# ESP32C3 register map
File version: 1.0
CPU: RISC-V RV32IMC single-core 1, little endian, no MPU, FPU, 3 interrupt priority bits
Registers are 32-bit, read-write, reset 0x0 unless marked. A register's access mark holds for its fields unless they carry their own. Offsets are from the block's base; [hi:lo] are bit positions; {n}, {i} and the like mark numbered series.

## SPI_MEM
Base 0x00000000
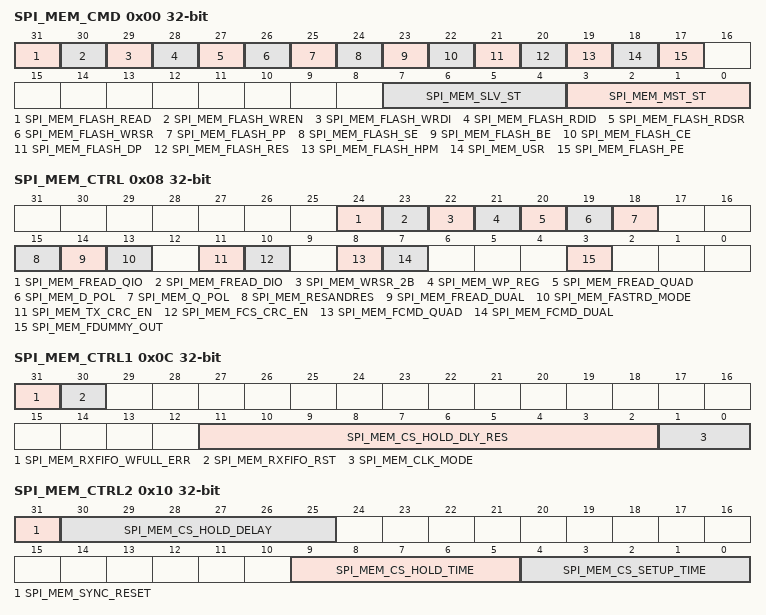
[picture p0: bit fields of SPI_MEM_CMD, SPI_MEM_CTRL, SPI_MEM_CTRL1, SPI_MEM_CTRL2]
0x00 SPI_MEM_CMD access per field
  [31] SPI_MEM_FLASH_READ rw, [30] SPI_MEM_FLASH_WREN rw, [29] SPI_MEM_FLASH_WRDI rw, [28] SPI_MEM_FLASH_RDID rw, [27] SPI_MEM_FLASH_RDSR rw, [26] SPI_MEM_FLASH_WRSR rw, [25] SPI_MEM_FLASH_PP rw, [24] SPI_MEM_FLASH_SE rw, [23] SPI_MEM_FLASH_BE rw, [22] SPI_MEM_FLASH_CE rw, [21] SPI_MEM_FLASH_DP rw, [20] SPI_MEM_FLASH_RES rw, [19] SPI_MEM_FLASH_HPM rw, [18] SPI_MEM_USR rw, [17] SPI_MEM_FLASH_PE rw, [7:4] SPI_MEM_SLV_ST ro, [3:0] SPI_MEM_MST_ST ro
0x04 SPI_MEM_ADDR
  [31:0] SPI_MEM_USR_ADDR_VALUE
0x08 SPI_MEM_CTRL
  [24] SPI_MEM_FREAD_QIO, [23] SPI_MEM_FREAD_DIO, [22] SPI_MEM_WRSR_2B, [21] SPI_MEM_WP_REG, [20] SPI_MEM_FREAD_QUAD, [19] SPI_MEM_D_POL, [18] SPI_MEM_Q_POL, [15] SPI_MEM_RESANDRES, [14] SPI_MEM_FREAD_DUAL, [13] SPI_MEM_FASTRD_MODE, [11] SPI_MEM_TX_CRC_EN, [10] SPI_MEM_FCS_CRC_EN, [8] SPI_MEM_FCMD_QUAD, [7] SPI_MEM_FCMD_DUAL, [3] SPI_MEM_FDUMMY_OUT
0x0C SPI_MEM_CTRL1 access per field
  [31] SPI_MEM_RXFIFO_WFULL_ERR ro, [30] SPI_MEM_RXFIFO_RST wo, [11:2] SPI_MEM_CS_HOLD_DLY_RES rw, [1:0] SPI_MEM_CLK_MODE rw
0x10 SPI_MEM_CTRL2 access per field
  [31] SPI_MEM_SYNC_RESET wo, [30:25] SPI_MEM_CS_HOLD_DELAY rw, [9:5] SPI_MEM_CS_HOLD_TIME rw, [4:0] SPI_MEM_CS_SETUP_TIME rw
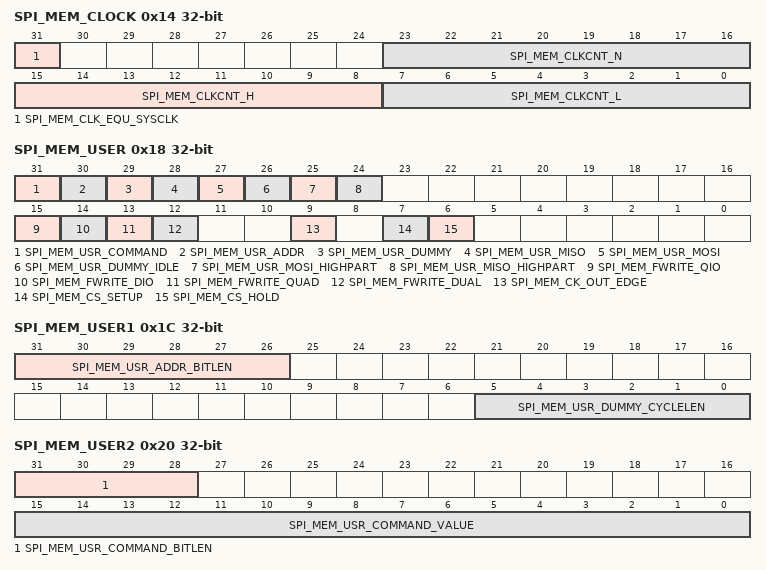
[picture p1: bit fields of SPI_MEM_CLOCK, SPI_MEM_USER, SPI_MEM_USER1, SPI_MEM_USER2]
0x14 SPI_MEM_CLOCK
  [31] SPI_MEM_CLK_EQU_SYSCLK, [23:16] SPI_MEM_CLKCNT_N, [15:8] SPI_MEM_CLKCNT_H, [7:0] SPI_MEM_CLKCNT_L
0x18 SPI_MEM_USER
  [31] SPI_MEM_USR_COMMAND, [30] SPI_MEM_USR_ADDR, [29] SPI_MEM_USR_DUMMY, [28] SPI_MEM_USR_MISO, [27] SPI_MEM_USR_MOSI, [26] SPI_MEM_USR_DUMMY_IDLE, [25] SPI_MEM_USR_MOSI_HIGHPART, [24] SPI_MEM_USR_MISO_HIGHPART, [15] SPI_MEM_FWRITE_QIO, [14] SPI_MEM_FWRITE_DIO, [13] SPI_MEM_FWRITE_QUAD, [12] SPI_MEM_FWRITE_DUAL, [9] SPI_MEM_CK_OUT_EDGE, [7] SPI_MEM_CS_SETUP, [6] SPI_MEM_CS_HOLD
0x1C SPI_MEM_USER1
  [31:26] SPI_MEM_USR_ADDR_BITLEN, [5:0] SPI_MEM_USR_DUMMY_CYCLELEN
0x20 SPI_MEM_USER2
  [31:28] SPI_MEM_USR_COMMAND_BITLEN, [15:0] SPI_MEM_USR_COMMAND_VALUE
0x24 SPI_MEM_MOSI_DLEN
  [9:0] SPI_MEM_USR_MOSI_DBITLEN
0x28 SPI_MEM_MISO_DLEN
  [9:0] SPI_MEM_USR_MISO_DBITLEN
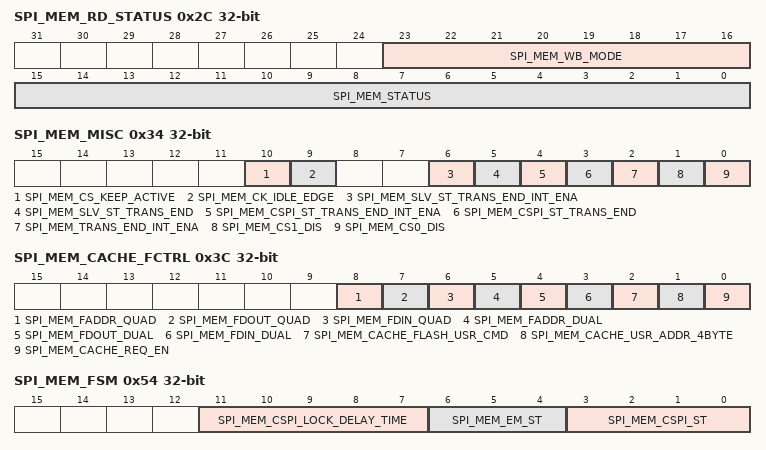
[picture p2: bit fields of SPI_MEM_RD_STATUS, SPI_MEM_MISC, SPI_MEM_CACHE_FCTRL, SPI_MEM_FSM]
0x2C SPI_MEM_RD_STATUS
  [23:16] SPI_MEM_WB_MODE, [15:0] SPI_MEM_STATUS
0x34 SPI_MEM_MISC
  [10] SPI_MEM_CS_KEEP_ACTIVE, [9] SPI_MEM_CK_IDLE_EDGE, [6] SPI_MEM_SLV_ST_TRANS_END_INT_ENA, [5] SPI_MEM_SLV_ST_TRANS_END, [4] SPI_MEM_CSPI_ST_TRANS_END_INT_ENA, [3] SPI_MEM_CSPI_ST_TRANS_END, [2] SPI_MEM_TRANS_END_INT_ENA, [1] SPI_MEM_CS1_DIS, [0] SPI_MEM_CS0_DIS
0x38 SPI_MEM_TX_CRC ro
  [31:0] SPI_MEM_TX_CRC_DATA
0x3C SPI_MEM_CACHE_FCTRL
  [8] SPI_MEM_FADDR_QUAD, [7] SPI_MEM_FDOUT_QUAD, [6] SPI_MEM_FDIN_QUAD, [5] SPI_MEM_FADDR_DUAL, [4] SPI_MEM_FDOUT_DUAL, [3] SPI_MEM_FDIN_DUAL, [2] SPI_MEM_CACHE_FLASH_USR_CMD, [1] SPI_MEM_CACHE_USR_ADDR_4BYTE, [0] SPI_MEM_CACHE_REQ_EN
0x54 SPI_MEM_FSM access per field
  [11:7] SPI_MEM_CSPI_LOCK_DELAY_TIME rw, [6:4] SPI_MEM_EM_ST ro, [3:0] SPI_MEM_CSPI_ST ro
{0x58+4i} SPI_MEM_W{i} (i=0..15)
  [31:0] SPI_MEM_BUF{i}
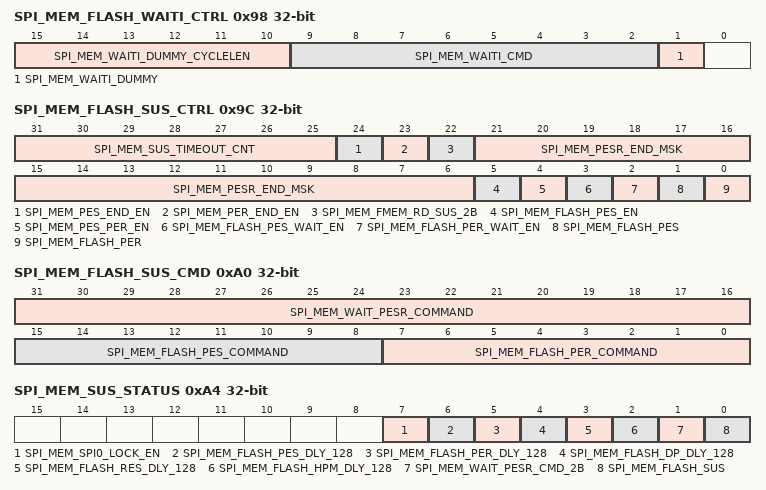
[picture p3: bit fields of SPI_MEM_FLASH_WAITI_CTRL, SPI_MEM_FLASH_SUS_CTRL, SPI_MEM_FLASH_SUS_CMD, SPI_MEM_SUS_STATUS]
0x98 SPI_MEM_FLASH_WAITI_CTRL
  [15:10] SPI_MEM_WAITI_DUMMY_CYCLELEN, [9:2] SPI_MEM_WAITI_CMD, [1] SPI_MEM_WAITI_DUMMY
0x9C SPI_MEM_FLASH_SUS_CTRL
  [31:25] SPI_MEM_SUS_TIMEOUT_CNT, [24] SPI_MEM_PES_END_EN, [23] SPI_MEM_PER_END_EN, [22] SPI_MEM_FMEM_RD_SUS_2B, [21:6] SPI_MEM_PESR_END_MSK, [5] SPI_MEM_FLASH_PES_EN, [4] SPI_MEM_PES_PER_EN, [3] SPI_MEM_FLASH_PES_WAIT_EN, [2] SPI_MEM_FLASH_PER_WAIT_EN, [1] SPI_MEM_FLASH_PES, [0] SPI_MEM_FLASH_PER
0xA0 SPI_MEM_FLASH_SUS_CMD
  [31:16] SPI_MEM_WAIT_PESR_COMMAND, [15:8] SPI_MEM_FLASH_PES_COMMAND, [7:0] SPI_MEM_FLASH_PER_COMMAND
0xA4 SPI_MEM_SUS_STATUS
  [7] SPI_MEM_SPI0_LOCK_EN, [6] SPI_MEM_FLASH_PES_DLY_128, [5] SPI_MEM_FLASH_PER_DLY_128, [4] SPI_MEM_FLASH_DP_DLY_128, [3] SPI_MEM_FLASH_RES_DLY_128, [2] SPI_MEM_FLASH_HPM_DLY_128, [1] SPI_MEM_WAIT_PESR_CMD_2B, [0] SPI_MEM_FLASH_SUS
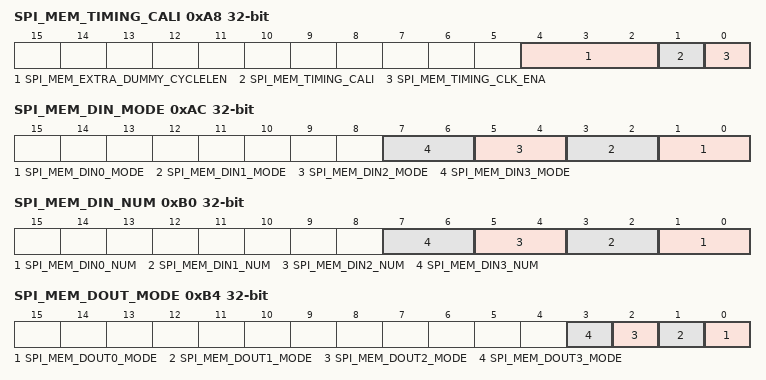
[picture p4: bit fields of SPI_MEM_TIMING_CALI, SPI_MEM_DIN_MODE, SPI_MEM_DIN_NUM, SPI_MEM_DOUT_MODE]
0xA8 SPI_MEM_TIMING_CALI
  [4:2] SPI_MEM_EXTRA_DUMMY_CYCLELEN, [1] SPI_MEM_TIMING_CALI, [0] SPI_MEM_TIMING_CLK_ENA
0xAC SPI_MEM_DIN_MODE
  [2n+1:2n] SPI_MEM_DIN{n}_MODE (n=0..3)
0xB0 SPI_MEM_DIN_NUM
  [2n+1:2n] SPI_MEM_DIN{n}_NUM (n=0..3)
0xB4 SPI_MEM_DOUT_MODE
  [n] SPI_MEM_DOUT{n}_MODE (n=0..3)
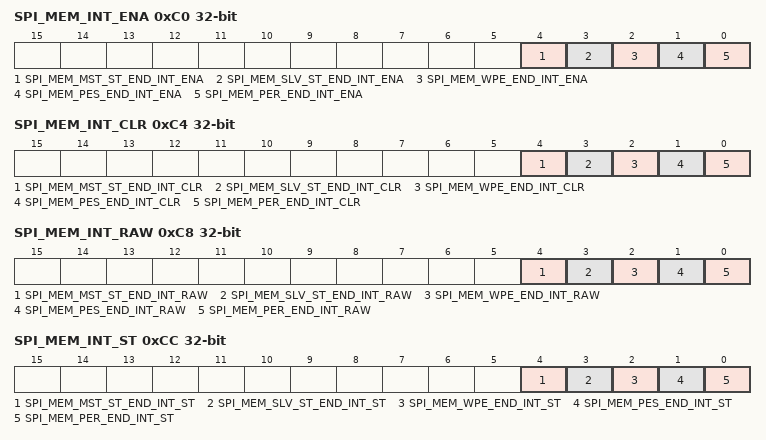
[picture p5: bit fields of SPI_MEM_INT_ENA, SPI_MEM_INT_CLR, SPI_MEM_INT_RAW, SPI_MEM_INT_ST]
0xC0 SPI_MEM_INT_ENA
  [4] SPI_MEM_MST_ST_END_INT_ENA, [3] SPI_MEM_SLV_ST_END_INT_ENA, [2] SPI_MEM_WPE_END_INT_ENA, [1] SPI_MEM_PES_END_INT_ENA, [0] SPI_MEM_PER_END_INT_ENA
0xC4 SPI_MEM_INT_CLR wo
  [4] SPI_MEM_MST_ST_END_INT_CLR, [3] SPI_MEM_SLV_ST_END_INT_CLR, [2] SPI_MEM_WPE_END_INT_CLR, [1] SPI_MEM_PES_END_INT_CLR, [0] SPI_MEM_PER_END_INT_CLR
0xC8 SPI_MEM_INT_RAW
  [4] SPI_MEM_MST_ST_END_INT_RAW, [3] SPI_MEM_SLV_ST_END_INT_RAW, [2] SPI_MEM_WPE_END_INT_RAW, [1] SPI_MEM_PES_END_INT_RAW, [0] SPI_MEM_PER_END_INT_RAW
0xCC SPI_MEM_INT_ST ro
  [4] SPI_MEM_MST_ST_END_INT_ST, [3] SPI_MEM_SLV_ST_END_INT_ST, [2] SPI_MEM_WPE_END_INT_ST, [1] SPI_MEM_PES_END_INT_ST, [0] SPI_MEM_PER_END_INT_ST
0xDC SPI_MEM_CLOCK_GATE
  [0] SPI_MEM_CLK_EN
0xE0 SPI_MEM_CORE_CLK_SEL
  [1:0] SPI_MEM_SPI01_CLK_SEL
0x3FC SPI_MEM_DATE
  [27:0] SPI_MEM_DATE
